VERSION ""

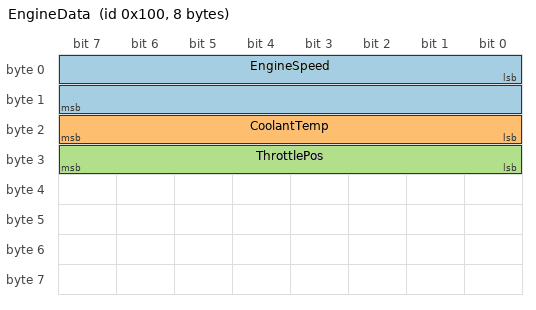
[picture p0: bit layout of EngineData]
BO_ 256 EngineData: 8 ECM
 SG_ EngineSpeed : 0|16@1+ (0.25,0) [0|16383.75] "rpm" Vector__XXX
 SG_ CoolantTemp : 16|8@1+ (1,-40) [-40|215] "degC" Vector__XXX
 SG_ ThrottlePos : 24|8@1+ (0.4,0) [0|102] "%" Vector__XXX

BO_ 257 VehicleState: 8 BCM
 SG_ VehicleSpeed : 7|16@0+ (0.01,0) [0|655.35] "km/h" Vector__XXX
 SG_ SteeringAngle : 23|16@0- (0.1,0) [-3276.8|3276.7] "deg" Vector__XXX
